# CY8C3866AXI_040 register map
File version: 0.1
CY8C38
Registers are 8-bit, read-write, no defined reset value unless marked. A register's access mark holds for its fields unless they carry their own. Offsets are from the block's base; lines under a group give offsets from that group; [hi:lo] are bit positions; {n}, {i} and the like mark numbered series; 'fields as' and 'values as' point back to an identical list; <NAME> marks a mode.

## Memory map
0x000043A7 Comp_1 size 0x17F0
0x000043AA ADC_DelSig_1 size 0x17E0
0x00006408 Timer_1 size 0x95
0x00006422 UART_1 size 0x145 — UART
0x00006423 UART_RBTQ1 size 0x45 — UART
0x0000644C UART_SABERTOOTH size 0x20 — UART
0x0000644E UART_RBTQ2 size 0x118 — UART
0x00006479 buzzerControl size 0x1

## UART_SABERTOOTH — UART
Base 0x0000644C
0x00 TX_UART_SABERTOOTH_TX_DATA — TX Data Register
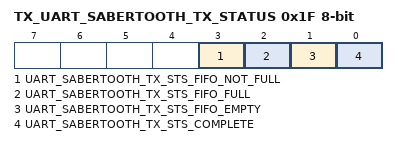
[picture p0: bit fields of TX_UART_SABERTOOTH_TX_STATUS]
0x1F TX_UART_SABERTOOTH_TX_STATUS — TX status register
  [3] UART_SABERTOOTH_TX_STS_FIFO_NOT_FULL ro, [2] UART_SABERTOOTH_TX_STS_FIFO_FULL ro, [1] UART_SABERTOOTH_TX_STS_FIFO_EMPTY ro, [0] UART_SABERTOOTH_TX_STS_COMPLETE ro

## buzzerControl
Base 0x00006479
0x00 buzzerControl_CONTROL_REG

## Timer_1
Base 0x00006408
0x00 Timer_1_COUNTER 32-bit — UDB.A0 - Current Down Counter Value
0x20 Timer_1_PERIOD 32-bit — UDB.D0 - Assigned Period
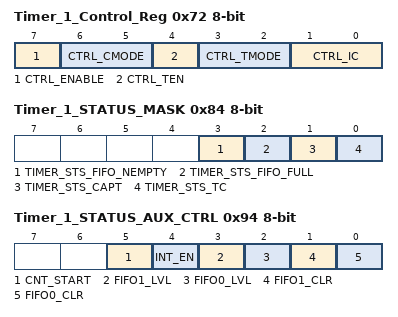
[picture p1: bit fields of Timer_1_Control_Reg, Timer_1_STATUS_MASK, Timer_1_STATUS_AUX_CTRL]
0x72 Timer_1_Control_Reg — UDB Control Register - Assigned Control Register Value
  [7] CTRL_ENABLE — Enable the Timer
  [6:5] CTRL_CMODE — Capture Mode
  [4] CTRL_TEN — Trigger Enable Bit
  [3:2] CTRL_TMODE — Trigger Mode
  [1:0] CTRL_IC — Interrupt Count
0x84 Timer_1_STATUS_MASK — UDB Status bits Interrupt Mask Enable Register
  [3] TIMER_STS_FIFO_NEMPTY ro — FIFO Empty status
  [2] TIMER_STS_FIFO_FULL ro — FIFO Full Status
  [1] TIMER_STS_CAPT ro — Enables the Interrupt on Capture
  [0] TIMER_STS_TC ro — Enables the Interrupt on TC
0x94 Timer_1_STATUS_AUX_CTRL — UDB Auxilliary Control Register
  [5] CNT_START — FIFO0 clear
    0=E_CNT_START0 (Disable counter); 1=E_CNT_START1 (Enable counter)
  [4] INT_EN
    0=E_INT_EN0 (Interrupt disabled); 1=E_INT_EN1 (Interrupt enabled)
  [3] FIFO1_LVL — FIFO level
    0=E_FIFO_LVL_0 (FIFO LVL: input mode: FIFO not full; output mode: FIFO not empty); 1=E_FIFO_LVL_1 (FIFO LVL: input mode: FIFO at least 1/2 empty; output mode: FIFO at least 1/2 full)
  [2] FIFO0_LVL — FIFO level
    values as FIFO1_LVL
  [1] FIFO1_CLR — FIFO1 clear
    0=E_FIFO_CLR_0 (Normal FIFO operation); 1=E_FIFO_CLR_1 (Clear FIFO state)
  [0] FIFO0_CLR — FIFO0 clear
    values as FIFO1_CLR

## UART_1 — UART
Base 0x00006422
0x00 RX_UART_1_RX_ADDRESS1 — RX Address1 Register
0x10 RX_UART_1_RX_ADDRESS2 — RX Address2 Register
0x20 RX_UART_1_RX_DATA — RX Data Register
0x25 TX_UART_1_TX_DATA — TX Data Register
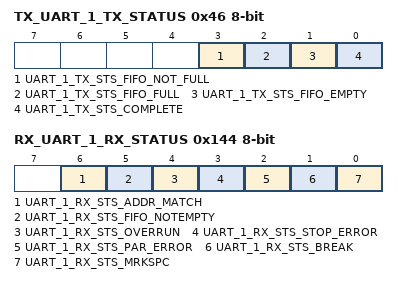
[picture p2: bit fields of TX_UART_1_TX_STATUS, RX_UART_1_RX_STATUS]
0x46 TX_UART_1_TX_STATUS — TX status register
  [3] UART_1_TX_STS_FIFO_NOT_FULL ro, [2] UART_1_TX_STS_FIFO_FULL ro, [1] UART_1_TX_STS_FIFO_EMPTY ro, [0] UART_1_TX_STS_COMPLETE ro
0x144 RX_UART_1_RX_STATUS — RX status register
  [6] UART_1_RX_STS_ADDR_MATCH ro, [5] UART_1_RX_STS_FIFO_NOTEMPTY ro, [4] UART_1_RX_STS_OVERRUN ro, [3] UART_1_RX_STS_STOP_ERROR ro, [2] UART_1_RX_STS_PAR_ERROR ro, [1] UART_1_RX_STS_BREAK ro, [0] UART_1_RX_STS_MRKSPC ro

## UART_RBTQ1 — UART
Base 0x00006423
0x00 RX_UART_RBTQ1_RX_ADDRESS1 — RX Address1 Register
0x10 RX_UART_RBTQ1_RX_ADDRESS2 — RX Address2 Register
0x1D TX_UART_RBTQ1_TX_DATA — TX Data Register
0x20 RX_UART_RBTQ1_RX_DATA — RX Data Register
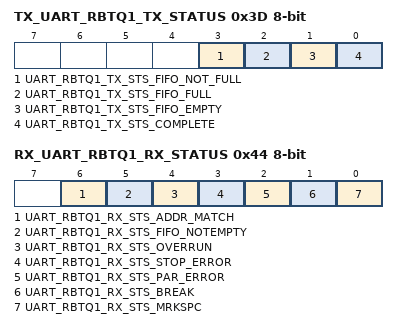
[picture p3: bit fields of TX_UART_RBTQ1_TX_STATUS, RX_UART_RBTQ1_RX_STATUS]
0x3D TX_UART_RBTQ1_TX_STATUS — TX status register
  [3] UART_RBTQ1_TX_STS_FIFO_NOT_FULL ro, [2] UART_RBTQ1_TX_STS_FIFO_FULL ro, [1] UART_RBTQ1_TX_STS_FIFO_EMPTY ro, [0] UART_RBTQ1_TX_STS_COMPLETE ro
0x44 RX_UART_RBTQ1_RX_STATUS — RX status register
  [6] UART_RBTQ1_RX_STS_ADDR_MATCH ro, [5] UART_RBTQ1_RX_STS_FIFO_NOTEMPTY ro, [4] UART_RBTQ1_RX_STS_OVERRUN ro, [3] UART_RBTQ1_RX_STS_STOP_ERROR ro, [2] UART_RBTQ1_RX_STS_PAR_ERROR ro, [1] UART_RBTQ1_RX_STS_BREAK ro, [0] UART_RBTQ1_RX_STS_MRKSPC ro
